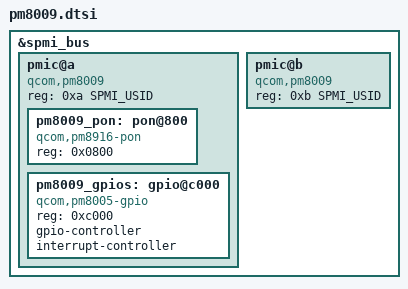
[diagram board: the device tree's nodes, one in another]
// SPDX-License-Identifier: BSD-3-Clause
/*
 * Copyright (c) 2017-2019, The Linux Foundation. All rights reserved.
 * Copyright (c) 2020, Linaro Limited
 */

#include <dt-bindings/spmi/spmi.h>

&spmi_bus {
	pmic@a {
		compatible = "qcom,pm8009", "qcom,spmi-pmic";
		reg = <0xa SPMI_USID>;
		#address-cells = <1>;
		#size-cells = <0>;

		pm8009_pon: pon@800 {
			compatible = "qcom,pm8916-pon";
			reg = <0x0800>;
		};

		pm8009_gpios: gpio@c000 {
			compatible = "qcom,pm8005-gpio";
			reg = <0xc000>;
			gpio-controller;
			#gpio-cells = <2>;
			interrupt-controller;
			#interrupt-cells = <2>;
		};
	};

	pmic@b {
		compatible = "qcom,pm8009", "qcom,spmi-pmic";
		reg = <0xb SPMI_USID>;
		#address-cells = <1>;
		#size-cells = <0>;
	};
};
